# TLE987x register map
Vendor: Infineon; File version: 4.2
TLE987x Family
CPU: CM3 r0p0, little endian, no MPU, no FPU, 4 interrupt priority bits
Registers are 32-bit, read-write, reset 0x0 unless marked. A register's access mark holds for its fields unless they carry their own. Offsets are from the block's base; lines under a group give offsets from that group; [hi:lo] are bit positions; {n}, {i} and the like mark numbered series; 'fields as' and 'values as' point back to an identical list; <NAME> marks a mode.

## Memory map
0x40004000 ADC1 size 0x4000 — ADC1 Module
0x40008000 ADC34 size 0x4000
0x4000C000 CCU6 size 0x4000 — Capture Compare Unit 6
0x40010000 GPT12E size 0x4000 — General Purpose Timer 12E
0x40034000 BDRV size 0x4000 — Bridge Driver
0x48004000 TIMER2 size 0x1000 — TIMER2 Module
0x48005000 TIMER21 size 0x1000 — TIMER21 Module
0x48006000 TIMER3 size 0x21 — TIMER3 Module
0x48018000 MF size 0x4000 — Measurement Function
0x4801C000 ADC2 size 0x2000 — ADC2 Module
0x4801E000 LIN size 0x8 — Local Interconnect Network
0x48020000 UART1 size 0x2000 — UART1 Module
0x48022000 UART2 size 0x2000 — UART2 Module
0x48024000 SSC1 size 0x2000 — SSC1 Module
0x48026000 SSC2 size 0x2000 — SSC2 Module
0x48028000 PORT size 0x2000 — GPIO PORTs
0x50004000 PMU size 0x1000 — Power Management Unit
0x50005000 SCU size 0x1000 — System Control Unit
0x50006000 SCUPM size 0x1000 — System Control Unit for Power Modules
0x50014000 DMA size 0x4000 — Direct Memeory Access
0xE000E000 CPU size 0x1000 — CPU Core

## Interrupts
0 GPT1_Int (GPT12E) — Interrupt node 0: GPT1 Block
1 GPT2_Int (GPT12E) — Interrupt node 1: GPT2 Block
2 ADC2_Tmr3_Int (ADC2) — Interrupt node 2: ADC2, Timer3, BEMF, ADC3/4
3 ADC1_VREF5_Int (ADC1) — Interrupt node 3: ADC1, VAREF
4 CCU6_SR0_Int (CCU6) — Interrupt node 4: CCU6 node0
5 CCU6_SR1_Int (CCU6) — Interrupt node 5: CCU6 node1
6 CCU6_SR2_Int (CCU6) — Interrupt node 6: CCU6 node2
7 CCU6_SR3_Int (CCU6) — Interrupt node 7: CCU6 node3
8 SSC1_Int (SSC1) — Interrupt node 8: SSC1
9 SSC2_Int (SSC2) — Interrupt node 9: SSC2
10 UART1_LIN_Tmr2_Int (UART1) — Interrupt node10: UART1(ASC,LIN), Timer2
11 UART2_Tmr21_EINT2_Int (UART2) — Interrupt node11: UART2, Timer21, EINT2
12 EXINT0_MON_Int (SCU) — Interrupt node12: EINT0, MON
13 EXINT1_Int (SCU) — Interrupt node13: EINT1
14 BDRV_CP_Int (BDRV) — Interrupt node14: BDRV, Charge Pump
15 DMA_Int (DMA) — Interrupt node15: DMA

## ADC34
Base 0x40008000
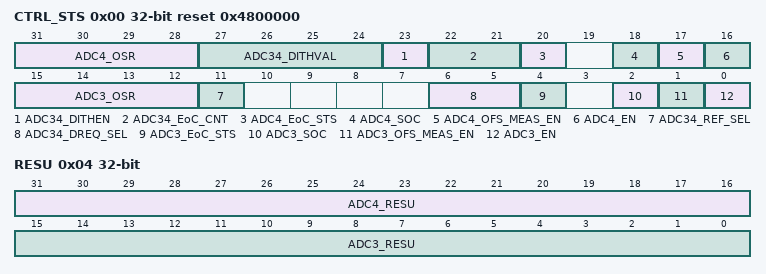
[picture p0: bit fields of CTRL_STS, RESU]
0x00 CTRL_STS access per field reset 0x4800000 — ADC3 and ADC4 Control and Status
  [31:28] ADC4_OSR rw — ADC4 Oversampling Ratio
    7=Factor 128; 8=Factor 256; 9=Factor 512; 10=Factor 1024; 11=Factor 2048
  [27:24] ADC34_DITHVAL rw — ADC34 Dither Value
  [23] ADC34_DITHEN rw — ADC34 Dithering Enable
    0=Disable (ADC34 Dithering); 1=Enable (ADC34 Dithering)
  [22:21] ADC34_EoC_CNT rw — ADC34 EoC counter
    0=ADC IRQ with every EoC; 1=ADC IRQ with every 8th EoC; 2=ADC IRQ with every 16th EoC; 3=ADC IRQ with every 32nd EoC
  [20] ADC4_EoC_STS ro — ADC4 End of Conversion
    0=Conversion ongoing (ADC4 conversion still in progress); 1=Conversion finished (ADC4 conversion terminated)
  [18] ADC4_SOC rw — ADC4 conversion enable (set after enabling ADC to allow settling of the analog converter part)
    0=Disable (ADC4 data processing); 1=Enable (ADC4 data processing)
  [17] ADC4_OFS_MEAS_EN rw — ADC4 Offset Measurement Enable
    0=DISABLE (Offset Measurement); 1=ENABLE (Offset Measurement)
  [16] ADC4_EN rw — ADC4 analog frontend Enable
    0=DISABLE (ADC4 analog frontend switched off); 1=ENABLE (ADC4 analog frontend switched on)
  [15:12] ADC3_OSR rw — ADC3 Oversampling Ratio
    values as ADC4_OSR
  [11] ADC34_REF_SEL rw — ADC34 reference voltage selection
    0=VAREF (use VAREF / VAGND as reference); 1=VDD_EXT (use VDD_EXT / GND as reference)
  [6:5] ADC34_DREQ_SEL ro — DMA Ch13 request source select
    0=no_DMA_request (DMA request masked for both SDADCs); 1=ADC3_DREQ (only ADC3_EOC triggers DMA Ch13 request); 2=ADC4_DREQ (only ADC4_EOC triggers DMA Ch13 request); 3=ADC34_DREQ (ADC3_EOC or ADC4_EOC triggers DMA Ch13 request)
  [4] ADC3_EoC_STS ro — ADC3 End of Conversion
    0=Conversion ongoing (ADC3 conversion still in progress); 1=Conversion finished (ADC3 conversion terminated)
  [2] ADC3_SOC rw — ADC3 conversion enable (set after enabling ADC to allow settling of the analog converter part)
    0=Disable (ADC3 data processing); 1=Enable (ADC3 data processing)
  [1] ADC3_OFS_MEAS_EN rw — ADC3 Offset Measurement Enable
    values as ADC4_OFS_MEAS_EN
  [0] ADC3_EN rw — ADC3 analog frontend Enable
    0=DISABLE (ADC3 analog frontend switched off); 1=ENABLE (ADC3 analog frontend switched on)
0x04 RESU ro — ADC3_ADC4_RESU
  [31:16] ADC4_RESU — ADC4 Result Register
  [15:0] ADC3_RESU — ADC3 Result Register
